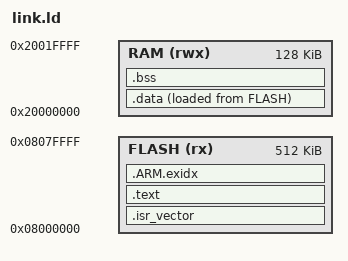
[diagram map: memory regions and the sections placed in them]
/* STM32L452RE: 512 KB flash, 128 KB SRAM1 */
ENTRY(resetHandler)

MEMORY
{
  FLASH (rx)  : ORIGIN = 0x08000000, LENGTH = 512K
  RAM   (rwx) : ORIGIN = 0x20000000, LENGTH = 128K
}

_estack = ORIGIN(RAM) + LENGTH(RAM);

SECTIONS
{
  .isr_vector : { KEEP(*(.isr_vector)) } > FLASH

  .text : {
    *(.text*)
    *(.rodata*)
    . = ALIGN(4);
  } > FLASH

  .ARM.exidx : { *(.ARM.exidx*) } > FLASH

  .data : {
    _sdata = .;
    *(.data*)
    . = ALIGN(4);
    _edata = .;
  } > RAM AT > FLASH
  _sidata = LOADADDR(.data);

  .bss (NOLOAD) : {
    _sbss = .;
    *(.bss*)
    *(COMMON)
    . = ALIGN(4);
    _ebss = .;
  } > RAM
}
